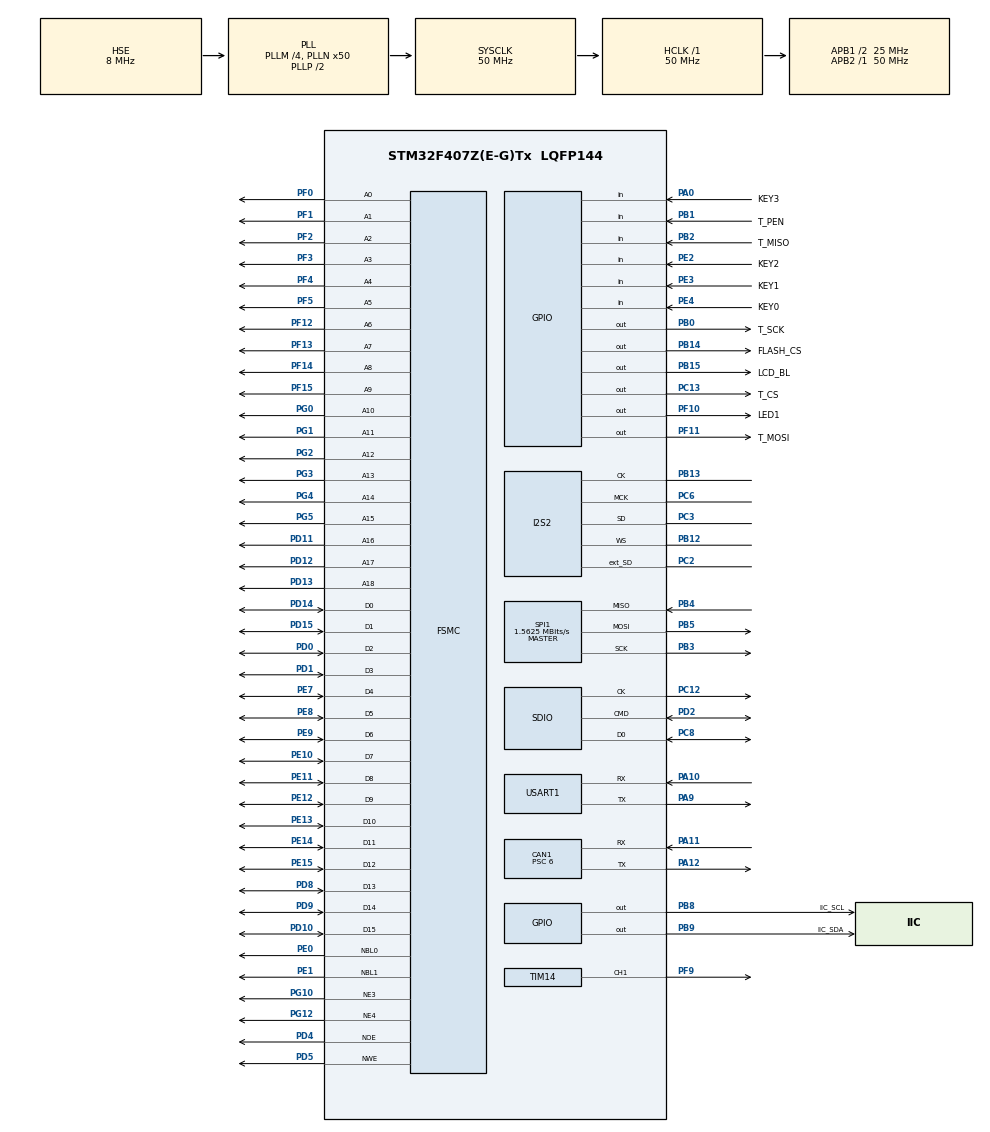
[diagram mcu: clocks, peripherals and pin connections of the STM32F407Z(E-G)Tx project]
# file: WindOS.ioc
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CAN1.BS1=CAN_BS1_7TQ
CAN1.BS2=CAN_BS2_6TQ
CAN1.CalculateBaudRate=297619
CAN1.CalculateTimeBit=3360
CAN1.CalculateTimeQuantum=240.0
CAN1.Mode=CAN_MODE_LOOPBACK
CAN1.NART=DISABLE
CAN1.Prescaler=6
Dma.Request0=SPI2_TX
Dma.SPI2_TX.0.Direction=DMA_MEMORY_TO_PERIPH
Dma.SPI2_TX.0.FIFOMode=DMA_FIFOMODE_DISABLE
Dma.SPI2_TX.0.Instance=DMA1_Stream4
Dma.SPI2_TX.0.MemDataAlignment=DMA_MDATAALIGN_HALFWORD
Dma.SPI2_TX.0.MemInc=DMA_MINC_ENABLE
Dma.SPI2_TX.0.Mode=DMA_CIRCULAR
Dma.SPI2_TX.0.PeriphDataAlignment=DMA_PDATAALIGN_HALFWORD
Dma.SPI2_TX.0.PeriphInc=DMA_PINC_DISABLE
Dma.SPI2_TX.0.Priority=DMA_PRIORITY_HIGH
FREERTOS.Tasks01=defaultTask,0,2048,StartDefaultTask,Default,NULL,Dynamic,NULL,NULL
FREERTOS.configCHECK_FOR_STACK_OVERFLOW=2
FREERTOS.configTOTAL_HEAP_SIZE=20480
FREERTOS.configUSE_TICK_HOOK=1
FSMC.DataSetupTime1=60
FSMC.ExtendedAddressSetupTime1=8
FSMC.ExtendedDataSetupTime1=9
FSMC.ExtendedMode1=FSMC_EXTENDED_MODE_ENABLE
FSMC.ExtendedMode2=FSMC_EXTENDED_MODE_DISABLE
FSMC.WriteOperation1=FSMC_WRITE_OPERATION_ENABLE
FSMC.WriteOperation2=FSMC_WRITE_OPERATION_ENABLE
I2S2.AudioFreq=I2S_AUDIOFREQ_8K
I2S2.DataFormat=I2S_DATAFORMAT_16B_EXTENDED
I2S2.ErrorAudioFreq=-0.27 %
I2S2.FullDuplexMode=I2S_FULLDUPLEXMODE_ENABLE
I2S2.Instance=SPI$Index
I2S2.RealAudioFreq=7.978 KHz
I2S2.VirtualMode=I2S_MODE_MASTER
Mcu.Family=STM32F4
Mcu.Name=STM32F407Z(E-G)Tx
Mcu.Package=LQFP144
NVIC.DMA1_Stream4_IRQn=true\:5\:0\:false\:false\:true\:true\:false\:true\:true
NVIC.PriorityGroup=NVIC_PRIORITYGROUP_4
NVIC.TIM2_IRQn=true\:15\:0\:false\:false\:true\:false\:false\:true\:true
NVIC.TIM6_DAC_IRQn=true\:5\:0\:false\:false\:true\:true\:true\:true\:true
NVIC.TimeBase=TIM2_IRQn
NVIC.TimeBaseIP=TIM2
NVIC.USART1_IRQn=true\:5\:0\:false\:false\:true\:true\:true\:true\:true
PA0-WKUP.GPIO_Label=KEY3
PA0-WKUP.Signal=GPIO_Input
PA10.Mode=Asynchronous
PA10.Signal=USART1_RX
PA11.GPIO_PuPd=GPIO_PULLUP
PA11.GPIO_Speed=GPIO_SPEED_FREQ_HIGH
PA11.Mode=CAN_Activate
PA11.Signal=CAN1_RX
PA12.GPIO_PuPd=GPIO_PULLUP
PA12.GPIO_Speed=GPIO_SPEED_FREQ_HIGH
PA12.Mode=CAN_Activate
PA12.Signal=CAN1_TX
PA13.Mode=Serial_Wire
PA13.Signal=SYS_JTMS-SWDIO
PA14.Mode=Serial_Wire
PA14.Signal=SYS_JTCK-SWCLK
PA9.Mode=Asynchronous
PA9.Signal=USART1_TX
PB0.GPIO_Label=T_SCK
PB0.GPIO_PuPd=GPIO_PULLUP
PB0.GPIO_Speed=GPIO_SPEED_FREQ_VERY_HIGH
PB0.Signal=GPIO_Output
PB1.GPIO_Label=T_PEN
PB1.GPIO_PuPd=GPIO_PULLUP
PB1.Signal=GPIO_Input
PB12.GPIO_PuPd=GPIO_PULLUP
PB12.GPIO_Speed=GPIO_SPEED_FREQ_HIGH
PB12.Mode=Full_Duplex_Master
PB12.Signal=I2S2_WS
PB13.GPIO_PuPd=GPIO_PULLUP
PB13.GPIO_Speed=GPIO_SPEED_FREQ_HIGH
PB13.Mode=Full_Duplex_Master
PB13.Signal=I2S2_CK
PB14.GPIO_Label=FLASH_CS
PB14.GPIO_PuPd=GPIO_PULLUP
PB14.GPIO_Speed=GPIO_SPEED_FREQ_VERY_HIGH
PB14.PinState=GPIO_PIN_SET
PB14.Signal=GPIO_Output
PB15.GPIO_Label=LCD_BL
PB15.Signal=GPIO_Output
PB2.GPIO_Label=T_MISO
PB2.GPIO_PuPd=GPIO_PULLUP
PB2.Signal=GPIO_Input
PB3.GPIO_PuPd=GPIO_PULLUP
PB3.Mode=Full_Duplex_Master
PB3.Signal=SPI1_SCK
PB4.GPIO_PuPd=GPIO_PULLUP
PB4.Mode=Full_Duplex_Master
PB4.Signal=SPI1_MISO
PB5.GPIO_PuPd=GPIO_PULLUP
PB5.Mode=Full_Duplex_Master
PB5.Signal=SPI1_MOSI
PB8.GPIO_Label=IIC_SCL
PB8.GPIO_ModeDefaultOutputPP=GPIO_MODE_OUTPUT_PP
PB8.GPIO_PuPd=GPIO_PULLUP
PB8.GPIO_Speed=GPIO_SPEED_FREQ_VERY_HIGH
PB8.Signal=GPIO_Output
PB9.GPIO_Label=IIC_SDA
PB9.GPIO_ModeDefaultOutputPP=GPIO_MODE_OUTPUT_OD
PB9.GPIO_PuPd=GPIO_PULLUP
PB9.GPIO_Speed=GPIO_SPEED_FREQ_VERY_HIGH
PB9.PinState=GPIO_PIN_RESET
PB9.Signal=GPIO_Output
PC12.GPIO_PuPd=GPIO_PULLUP
PC12.Mode=SD_1_bit
PC12.Signal=SDIO_CK
PC13-ANTI_TAMP.GPIO_Label=T_CS
PC13-ANTI_TAMP.GPIO_PuPd=GPIO_PULLUP
PC13-ANTI_TAMP.Signal=GPIO_Output
PC14-OSC32_IN.Mode=LSE-External-Oscillator
PC14-OSC32_IN.Signal=RCC_OSC32_IN
PC15-OSC32_OUT.Mode=LSE-External-Oscillator
PC15-OSC32_OUT.Signal=RCC_OSC32_OUT
PC2.GPIO_PuPd=GPIO_PULLUP
PC2.GPIO_Speed=GPIO_SPEED_FREQ_HIGH
PC2.Mode=Full_Duplex_Master
PC2.Signal=I2S2_ext_SD
PC3.GPIO_PuPd=GPIO_PULLUP
PC3.GPIO_Speed=GPIO_SPEED_FREQ_HIGH
PC3.Mode=Full_Duplex_Master
PC3.Signal=I2S2_SD
PC6.GPIO_PuPd=GPIO_PULLUP
PC6.GPIO_Speed=GPIO_SPEED_FREQ_HIGH
PC6.Mode=Master_Clock_Activated
PC6.Signal=I2S2_MCK
PC8.GPIO_PuPd=GPIO_PULLUP
PC8.Mode=SD_1_bit
PC8.Signal=SDIO_D0
PD0.Signal=FSMC_D2_DA2
PD1.Signal=FSMC_D3_DA3
PD10.Signal=FSMC_D15_DA15
PD11.Signal=FSMC_A16_CLE
PD12.Signal=FSMC_A17_ALE
PD13.Signal=FSMC_A18
PD14.Signal=FSMC_D0_DA0
PD15.Signal=FSMC_D1_DA1
PD2.GPIO_PuPd=GPIO_PULLUP
PD2.Mode=SD_1_bit
PD2.Signal=SDIO_CMD
PD4.Signal=FSMC_NOE
PD5.Signal=FSMC_NWE
PD8.Signal=FSMC_D13_DA13
PD9.Signal=FSMC_D14_DA14
PE0.Signal=FSMC_NBL0
PE1.Signal=FSMC_NBL1
PE10.Signal=FSMC_D7_DA7
PE11.Signal=FSMC_D8_DA8
PE12.Signal=FSMC_D9_DA9
PE13.Signal=FSMC_D10_DA10
PE14.Signal=FSMC_D11_DA11
PE15.Signal=FSMC_D12_DA12
PE2.GPIO_Label=KEY2
PE2.GPIO_PuPd=GPIO_PULLUP
PE2.Signal=GPIO_Input
PE3.GPIO_Label=KEY1
PE3.GPIO_PuPd=GPIO_PULLUP
PE3.Signal=GPIO_Input
PE4.GPIO_Label=KEY0
PE4.GPIO_PuPd=GPIO_PULLUP
PE4.Signal=GPIO_Input
PE7.Signal=FSMC_D4_DA4
PE8.Signal=FSMC_D5_DA5
PE9.Signal=FSMC_D6_DA6
PF0.Signal=FSMC_A0
PF1.Signal=FSMC_A1
PF10.GPIO_Label=LED1
PF10.PinState=GPIO_PIN_SET
PF10.Signal=GPIO_Output
PF11.GPIO_Label=T_MOSI
PF11.GPIO_ModeDefaultOutputPP=GPIO_MODE_OUTPUT_PP
PF11.GPIO_PuPd=GPIO_PULLUP
PF11.GPIO_Speed=GPIO_SPEED_FREQ_VERY_HIGH
PF11.Signal=GPIO_Output
PF12.Signal=FSMC_A6
PF13.Signal=FSMC_A7
PF14.Signal=FSMC_A8
PF15.Signal=FSMC_A9
PF2.Signal=FSMC_A2
PF3.Signal=FSMC_A3
PF4.Signal=FSMC_A4
PF5.Signal=FSMC_A5
PF9.Signal=S_TIM14_CH1
PG0.Signal=FSMC_A10
PG1.Signal=FSMC_A11
PG10.Mode=NorPsramChipSelect3_2
PG10.Signal=FSMC_NE3
PG12.Mode=NorPsramChipSelect4_1
PG12.Signal=FSMC_NE4
PG2.Signal=FSMC_A12
PG3.Signal=FSMC_A13
PG4.Signal=FSMC_A14
PG5.Signal=FSMC_A15
PH0-OSC_IN.Mode=HSE-External-Oscillator
PH0-OSC_IN.Signal=RCC_OSC_IN
PH1-OSC_OUT.Mode=HSE-External-Oscillator
PH1-OSC_OUT.Signal=RCC_OSC_OUT
ProjectManager.HeapSize=0x200
ProjectManager.StackSize=0x400
ProjectManager.TargetToolchain=Makefile
RCC.48MHZClocksFreq_Value=33333333.333333332
RCC.AHBFreq_Value=50000000
RCC.APB1CLKDivider=RCC_HCLK_DIV2
RCC.APB1Freq_Value=25000000
RCC.APB1TimFreq_Value=50000000
RCC.APB2Freq_Value=50000000
RCC.APB2TimFreq_Value=50000000
RCC.CortexFreq_Value=50000000
RCC.HCLKFreq_Value=50000000
RCC.HSE_VALUE=8000000
RCC.HSI_VALUE=16000000
RCC.PLLM=4
RCC.PLLN=50
RCC.PLLQ=3
RCC.PLLSourceVirtual=RCC_PLLSOURCE_HSE
RCC.SYSCLKFreq_VALUE=50000000
RCC.SYSCLKSource=RCC_SYSCLKSOURCE_PLLCLK
RCC.VCOOutputFreq_Value=100000000
SDIO.ClockDiv=1
SDIO.HardwareFlowControl=SDIO_HARDWARE_FLOW_CONTROL_ENABLE
SH.FSMC_A0.0=FSMC_A0,16b-a1
SH.FSMC_A0.1=FSMC_A0,19b-a2
SH.FSMC_A1.0=FSMC_A1,16b-a1
SH.FSMC_A1.1=FSMC_A1,19b-a2
SH.FSMC_A10.0=FSMC_A10,16b-a1
SH.FSMC_A10.1=FSMC_A10,19b-a2
SH.FSMC_A11.0=FSMC_A11,16b-a1
SH.FSMC_A11.1=FSMC_A11,19b-a2
SH.FSMC_A12.0=FSMC_A12,16b-a1
SH.FSMC_A12.1=FSMC_A12,19b-a2
SH.FSMC_A13.0=FSMC_A13,16b-a1
SH.FSMC_A13.1=FSMC_A13,19b-a2
SH.FSMC_A14.0=FSMC_A14,16b-a1
SH.FSMC_A14.1=FSMC_A14,19b-a2
SH.FSMC_A15.0=FSMC_A15,16b-a1
SH.FSMC_A15.1=FSMC_A15,19b-a2
SH.FSMC_A16_CLE.0=FSMC_A16,19b-a2
SH.FSMC_A17_ALE.0=FSMC_A17,19b-a2
SH.FSMC_A18.0=FSMC_A18,19b-a2
SH.FSMC_A2.0=FSMC_A2,16b-a1
SH.FSMC_A2.1=FSMC_A2,19b-a2
SH.FSMC_A3.0=FSMC_A3,16b-a1
SH.FSMC_A3.1=FSMC_A3,19b-a2
SH.FSMC_A4.0=FSMC_A4,16b-a1
SH.FSMC_A4.1=FSMC_A4,19b-a2
SH.FSMC_A5.0=FSMC_A5,16b-a1
SH.FSMC_A5.1=FSMC_A5,19b-a2
SH.FSMC_A6.0=FSMC_A6,16b-a1
SH.FSMC_A6.1=FSMC_A6,19b-a2
SH.FSMC_A7.0=FSMC_A7,16b-a1
SH.FSMC_A7.1=FSMC_A7,19b-a2
SH.FSMC_A8.0=FSMC_A8,16b-a1
SH.FSMC_A8.1=FSMC_A8,19b-a2
SH.FSMC_A9.0=FSMC_A9,16b-a1
SH.FSMC_A9.1=FSMC_A9,19b-a2
SH.FSMC_D0_DA0.0=FSMC_D0,16b-d1
SH.FSMC_D0_DA0.1=FSMC_D0,16b-d2
SH.FSMC_D10_DA10.0=FSMC_D10,16b-d1
SH.FSMC_D10_DA10.1=FSMC_D10,16b-d2
SH.FSMC_D11_DA11.0=FSMC_D11,16b-d1
SH.FSMC_D11_DA11.1=FSMC_D11,16b-d2
SH.FSMC_D12_DA12.0=FSMC_D12,16b-d1
SH.FSMC_D12_DA12.1=FSMC_D12,16b-d2
SH.FSMC_D13_DA13.0=FSMC_D13,16b-d1
SH.FSMC_D13_DA13.1=FSMC_D13,16b-d2
SH.FSMC_D14_DA14.0=FSMC_D14,16b-d1
SH.FSMC_D14_DA14.1=FSMC_D14,16b-d2
SH.FSMC_D15_DA15.0=FSMC_D15,16b-d1
SH.FSMC_D15_DA15.1=FSMC_D15,16b-d2
SH.FSMC_D1_DA1.0=FSMC_D1,16b-d1
SH.FSMC_D1_DA1.1=FSMC_D1,16b-d2
SH.FSMC_D2_DA2.0=FSMC_D2,16b-d1
SH.FSMC_D2_DA2.1=FSMC_D2,16b-d2
SH.FSMC_D3_DA3.0=FSMC_D3,16b-d1
SH.FSMC_D3_DA3.1=FSMC_D3,16b-d2
SH.FSMC_D4_DA4.0=FSMC_D4,16b-d1
SH.FSMC_D4_DA4.1=FSMC_D4,16b-d2
SH.FSMC_D5_DA5.0=FSMC_D5,16b-d1
SH.FSMC_D5_DA5.1=FSMC_D5,16b-d2
SH.FSMC_D6_DA6.0=FSMC_D6,16b-d1
SH.FSMC_D6_DA6.1=FSMC_D6,16b-d2
SH.FSMC_D7_DA7.0=FSMC_D7,16b-d1
SH.FSMC_D7_DA7.1=FSMC_D7,16b-d2
SH.FSMC_D8_DA8.0=FSMC_D8,16b-d1
SH.FSMC_D8_DA8.1=FSMC_D8,16b-d2
SH.FSMC_D9_DA9.0=FSMC_D9,16b-d1
SH.FSMC_D9_DA9.1=FSMC_D9,16b-d2
SH.FSMC_NBL0.0=FSMC_NBL0,2ByteEnable2
SH.FSMC_NBL1.0=FSMC_NBL1,2ByteEnable2
SH.FSMC_NOE.0=FSMC_NOE,Sram1
SH.FSMC_NOE.1=FSMC_NOE,Sram2
SH.FSMC_NWE.0=FSMC_NWE,Sram1
SH.FSMC_NWE.1=FSMC_NWE,Sram2
SH.S_TIM14_CH1.0=TIM14_CH1,PWM Generation1 CH1
SPI1.BaudRatePrescaler=SPI_BAUDRATEPRESCALER_32
SPI1.CLKPhase=SPI_PHASE_2EDGE
SPI1.CLKPolarity=SPI_POLARITY_HIGH
SPI1.CalculateBaudRate=1.5625 MBits/s
SPI1.Direction=SPI_DIRECTION_2LINES
SPI1.Mode=SPI_MODE_MASTER
SPI1.VirtualType=VM_MASTER
TIM14.AutoReloadPreload=TIM_AUTORELOAD_PRELOAD_ENABLE
TIM14.Channel=TIM_CHANNEL_1
TIM14.Period=999
TIM14.Prescaler=8399
TIM14.Pulse=500
TIM6.AutoReloadPreload=TIM_AUTORELOAD_PRELOAD_ENABLE
TIM6.Period=39
TIM6.Prescaler=8399
TIM6.TIM_MasterOutputTrigger=TIM_TRGO_ENABLE
USART1.VirtualMode=VM_ASYNC
VP_FREERTOS_VS_CMSIS_V1.Mode=CMSIS_V1
VP_RNG_VS_RNG.Mode=RNG_Activate
VP_SYS_VS_tim2.Mode=TIM2
VP_TIM14_VS_ClockSourceINT.Mode=Enable_Timer
VP_TIM6_VS_ClockSourceINT.Mode=Enable_Timer
board=custom

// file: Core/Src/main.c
/* USER CODE BEGIN Header */
/**
  ******************************************************************************
  * @file           : main.c
  * @brief          : Main program body
  ******************************************************************************
  * @attention
  *
  * Copyright (c) 2025 STMicroelectronics.
  * All rights reserved.
  *
  * This software is licensed under terms that can be found in the LICENSE file
  * in the root directory of this software component.
  * If no LICENSE file comes with this software, it is provided AS-IS.
  *
  ******************************************************************************
  */
/* USER CODE END Header */
#include "main.h"
#include "cmsis_os.h"
#include "can.h"
#include "dma.h"
#include "i2s.h"
#include "rng.h"
#include "sdio.h"
#include "spi.h"
#include "tim.h"
#include "usart.h"
#include "gpio.h"
#include "fsmc.h"

/* USER CODE BEGIN Includes */
#include "fun_test.h"
#include "lvgl_gui.h"
#include <stdio.h>
/* USER CODE END Includes */

void SystemClock_Config(void);
void MX_FREERTOS_Init(void);

/* USER CODE BEGIN 0 */
volatile uint8_t tim_4ms_flag = 0;
volatile uint32_t tim_4ms_tick = 0;

int _write(int fd, char *ptr, int len) {
  HAL_UART_Transmit(&huart1, (uint8_t*)ptr, len, HAL_MAX_DELAY);
  return len;
}
/* USER CODE END 0 */

int main(void)
{

  /* MCU Configuration--------------------------------------------------------*/

  /* Reset of all peripherals, Initializes the Flash interface and the Systick. */
  HAL_Init();

  /* Configure the system clock */
  SystemClock_Config();

  /* Initialize all configured peripherals */
  MX_GPIO_Init();
  MX_DMA_Init();
  MX_USART1_UART_Init();
  MX_TIM6_Init();
  MX_FSMC_Init();
  MX_SPI1_Init();
  MX_CAN1_Init();
  MX_RNG_Init();
  MX_SDIO_SD_Init();
  MX_I2S2_Init();
  MX_TIM14_Init();
  /* USER CODE BEGIN 2 */
  lvgl_gui_init();
  test_mode_init();
  /* USER CODE END 2 */

  /* Call init function for freertos objects (in cmsis_os2.c) */
  MX_FREERTOS_Init();

  /* Start scheduler */
  osKernelStart();

  /* We should never get here as control is now taken by the scheduler */

  /* Infinite loop */
  while (1)
  {

  }
}

void SystemClock_Config(void)
{
  RCC_OscInitTypeDef RCC_OscInitStruct = {0};
  RCC_ClkInitTypeDef RCC_ClkInitStruct = {0};

  /** Configure the main internal regulator output voltage
  */
  __HAL_RCC_PWR_CLK_ENABLE();
  __HAL_PWR_VOLTAGESCALING_CONFIG(PWR_REGULATOR_VOLTAGE_SCALE1);

  /** Initializes the RCC Oscillators according to the specified parameters
  * in the RCC_OscInitTypeDef structure.
  */
  RCC_OscInitStruct.OscillatorType = RCC_OSCILLATORTYPE_HSE;
  RCC_OscInitStruct.HSEState = RCC_HSE_ON;
  RCC_OscInitStruct.PLL.PLLState = RCC_PLL_ON;
  RCC_OscInitStruct.PLL.PLLSource = RCC_PLLSOURCE_HSE;
  RCC_OscInitStruct.PLL.PLLM = 4;
  RCC_OscInitStruct.PLL.PLLN = 50;
  RCC_OscInitStruct.PLL.PLLP = RCC_PLLP_DIV2;
  RCC_OscInitStruct.PLL.PLLQ = 3;
  if (HAL_RCC_OscConfig(&RCC_OscInitStruct) != HAL_OK)
  {
    Error_Handler();
  }

  /** Initializes the CPU, AHB and APB buses clocks
  */
  RCC_ClkInitStruct.ClockType = RCC_CLOCKTYPE_HCLK|RCC_CLOCKTYPE_SYSCLK
                              |RCC_CLOCKTYPE_PCLK1|RCC_CLOCKTYPE_PCLK2;
  RCC_ClkInitStruct.SYSCLKSource = RCC_SYSCLKSOURCE_PLLCLK;
  RCC_ClkInitStruct.AHBCLKDivider = RCC_SYSCLK_DIV1;
  RCC_ClkInitStruct.APB1CLKDivider = RCC_HCLK_DIV2;
  RCC_ClkInitStruct.APB2CLKDivider = RCC_HCLK_DIV1;

  if (HAL_RCC_ClockConfig(&RCC_ClkInitStruct, FLASH_LATENCY_1) != HAL_OK)
  {
    Error_Handler();
  }
}

void HAL_TIM_PeriodElapsedCallback(TIM_HandleTypeDef *htim)
{
  if (htim->Instance == TIM2)
  {
    HAL_IncTick();
  }
  /* USER CODE BEGIN Callback 1 */
  if (htim->Instance == TIM6) {
    /* 4ms itmer */
    tim_4ms_tick++;
    tim_4ms_flag = 1;
  }
  /* USER CODE END Callback 1 */
}

void Error_Handler(void)
{
  __disable_irq();
  while (1)
  {
  }
}

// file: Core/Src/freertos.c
/* USER CODE BEGIN Header */
/**
  ******************************************************************************
  * File Name          : freertos.c
  * Description        : Code for freertos applications
  ******************************************************************************
  * @attention
  *
  * Copyright (c) 2025 STMicroelectronics.
  * All rights reserved.
  *
  * This software is licensed under terms that can be found in the LICENSE file
  * in the root directory of this software component.
  * If no LICENSE file comes with this software, it is provided AS-IS.
  *
  ******************************************************************************
  */
/* USER CODE END Header */

#include "FreeRTOS.h"
#include "task.h"
#include "main.h"
#include "cmsis_os.h"

/* USER CODE BEGIN Includes */
#include "key.h"
#include "spi_norflash.h"
#include "lvgl_port.h"
/* USER CODE END Includes */

/* USER CODE BEGIN Variables */
osThreadId keyTaskHandle;
osThreadId flashWriteTaskHandle;
osThreadId playerTaskHandle;

extern void player_task();
/* USER CODE END Variables */
osThreadId defaultTaskHandle;

void StartDefaultTask(void const * argument);

void MX_FREERTOS_Init(void); /* (MISRA C 2004 rule 8.1) */

/* GetIdleTaskMemory prototype (linked to static allocation support) */
void vApplicationGetIdleTaskMemory( StaticTask_t **ppxIdleTaskTCBBuffer, StackType_t **ppxIdleTaskStackBuffer, uint32_t *pulIdleTaskStackSize );

/* Hook prototypes */
void vApplicationTickHook(void);
void vApplicationStackOverflowHook(xTaskHandle xTask, signed char *pcTaskName);

/* USER CODE BEGIN 3 */
__weak void vApplicationTickHook( void )
{
   /* This function will be called by each tick interrupt if
   configUSE_TICK_HOOK is set to 1 in FreeRTOSConfig.h. User code can be
   added here, but the tick hook is called from an interrupt context, so
   code must not attempt to block, and only the interrupt safe FreeRTOS API
   functions can be used (those that end in FromISR()). */
}
/* USER CODE END 3 */

/* USER CODE BEGIN 4 */
__weak void vApplicationStackOverflowHook(xTaskHandle xTask, signed char *pcTaskName)
{
   /* Run time stack overflow checking is performed if
   configCHECK_FOR_STACK_OVERFLOW is defined to 1 or 2. This hook function is
   called if a stack overflow is detected. */
}
/* USER CODE END 4 */

/* USER CODE BEGIN GET_IDLE_TASK_MEMORY */
static StaticTask_t xIdleTaskTCBBuffer;
static StackType_t xIdleStack[configMINIMAL_STACK_SIZE];

void vApplicationGetIdleTaskMemory( StaticTask_t **ppxIdleTaskTCBBuffer, StackType_t **ppxIdleTaskStackBuffer, uint32_t *pulIdleTaskStackSize )
{
  *ppxIdleTaskTCBBuffer = &xIdleTaskTCBBuffer;
  *ppxIdleTaskStackBuffer = &xIdleStack[0];
  *pulIdleTaskStackSize = configMINIMAL_STACK_SIZE;
  /* place for user code */
}
/* USER CODE END GET_IDLE_TASK_MEMORY */

void MX_FREERTOS_Init(void) {

  /* Create the thread(s) */
  /* definition and creation of defaultTask */
  osThreadDef(defaultTask, StartDefaultTask, osPriorityNormal, 0, 2048);
  defaultTaskHandle = osThreadCreate(osThread(defaultTask), NULL);

  /* USER CODE BEGIN RTOS_THREADS */
  /* add threads, ... */
  osThreadDef(keyTask, key_scan, osPriorityNormal, 0, 256);
  keyTaskHandle = osThreadCreate(osThread(keyTask), NULL);

  osThreadDef(flashWriteTask, norflash_write_task, osPriorityNormal, 0, 128);
  flashWriteTaskHandle = osThreadCreate(osThread(flashWriteTask), NULL);

  osThreadDef(playerTask, player_task, osPriorityNormal, 0, 1024);
  playerTaskHandle = osThreadCreate(osThread(playerTask), NULL);
  /* USER CODE END RTOS_THREADS */

}

void StartDefaultTask(void const * argument)
{
  /* USER CODE BEGIN StartDefaultTask */
  /* Infinite loop */
  lv_port_task();
  /* USER CODE END StartDefaultTask */
}
